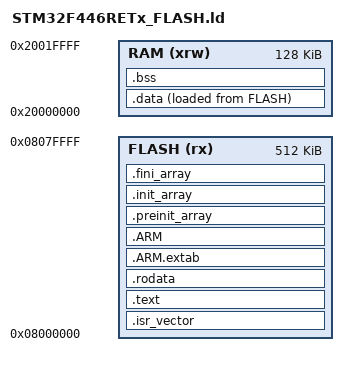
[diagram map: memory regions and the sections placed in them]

ENTRY(Reset_Handler)


_estack = ORIGIN(RAM) + LENGTH(RAM);

MEMORY {

    FLASH (rx) : ORIGIN = 0x08000000, LENGTH = 512k

    RAM (xrw) : ORIGIN = 0x20000000, LENGTH = 128k
}

SECTIONS {
    .isr_vector : {
        . = ALIGN(4);
        KEEP(*(.isr_vector))
        . = ALIGN(4);
    } >FLASH

    .text : {
        . = ALIGN(4);
        *(.text)
        *(.text*)
        . = ALIGN(4);
    } >FLASH

    .rodata : {
        . = ALIGN(4);
        *(.rodata)
        *(.rodata*)
        . = ALIGN(4);
    } >FLASH

    .ARM.extab : {
        . = ALIGN(4);
        *(.ARM.extab* .gnu.linkonce.armextab.*)
        . = ALIGN(4);
    } >FLASH

    .ARM : {
        . = ALIGN(4);
        __exidx_start = .;
        *(.ARM.exidx* .gnu.linkonce.armexidx.*)
        __exidx_end = .;
        . = ALIGN(4);
    } >FLASH

    .preinit_array : {
        . = ALIGN(4);
        PROVIDE_HIDDEN (__preinit_array_start = .);
        KEEP (*(.preinit_array*))
        PROVIDE_HIDDEN (__preinit_array_end = .);
        . = ALIGN(4);
    } >FLASH

    .init_array : {
        . = ALIGN(4);
        PROVIDE_HIDDEN (__init_array_start = .);
        KEEP (*(SORT(.init_array.*)))
        KEEP (*(.init_array*))
        PROVIDE_HIDDEN (__init_array_end = .);
        . = ALIGN(4);
    } >FLASH

    .fini_array : {
        . = ALIGN(4);
        PROVIDE_HIDDEN (__fini_array_start = .);
        KEEP (*(SORT(.fini_array.*)))
        KEEP (*(.fini_array*))
        PROVIDE_HIDDEN (__fini_array_end = .);
        . = ALIGN(4);
    } >FLASH

    _sidata = LOADADDR(.data);

    .data : {
        . = ALIGN(4);
        _sdata = .;
        *(.data)
        *(.data*)
        . = ALIGN(4);
        _edata = .;
    } >RAM AT>FLASH

    .bss : {
        . = ALIGN(4);
        _sbss = .;
        *(.bss)
        *(.bss*)
        *(COMMON)
        . = ALIGN(4);
        _ebss = .;
    } >RAM

    . = ALIGN(4);
    PROVIDE(end = .);
    PROVIDE(_end = .);
}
